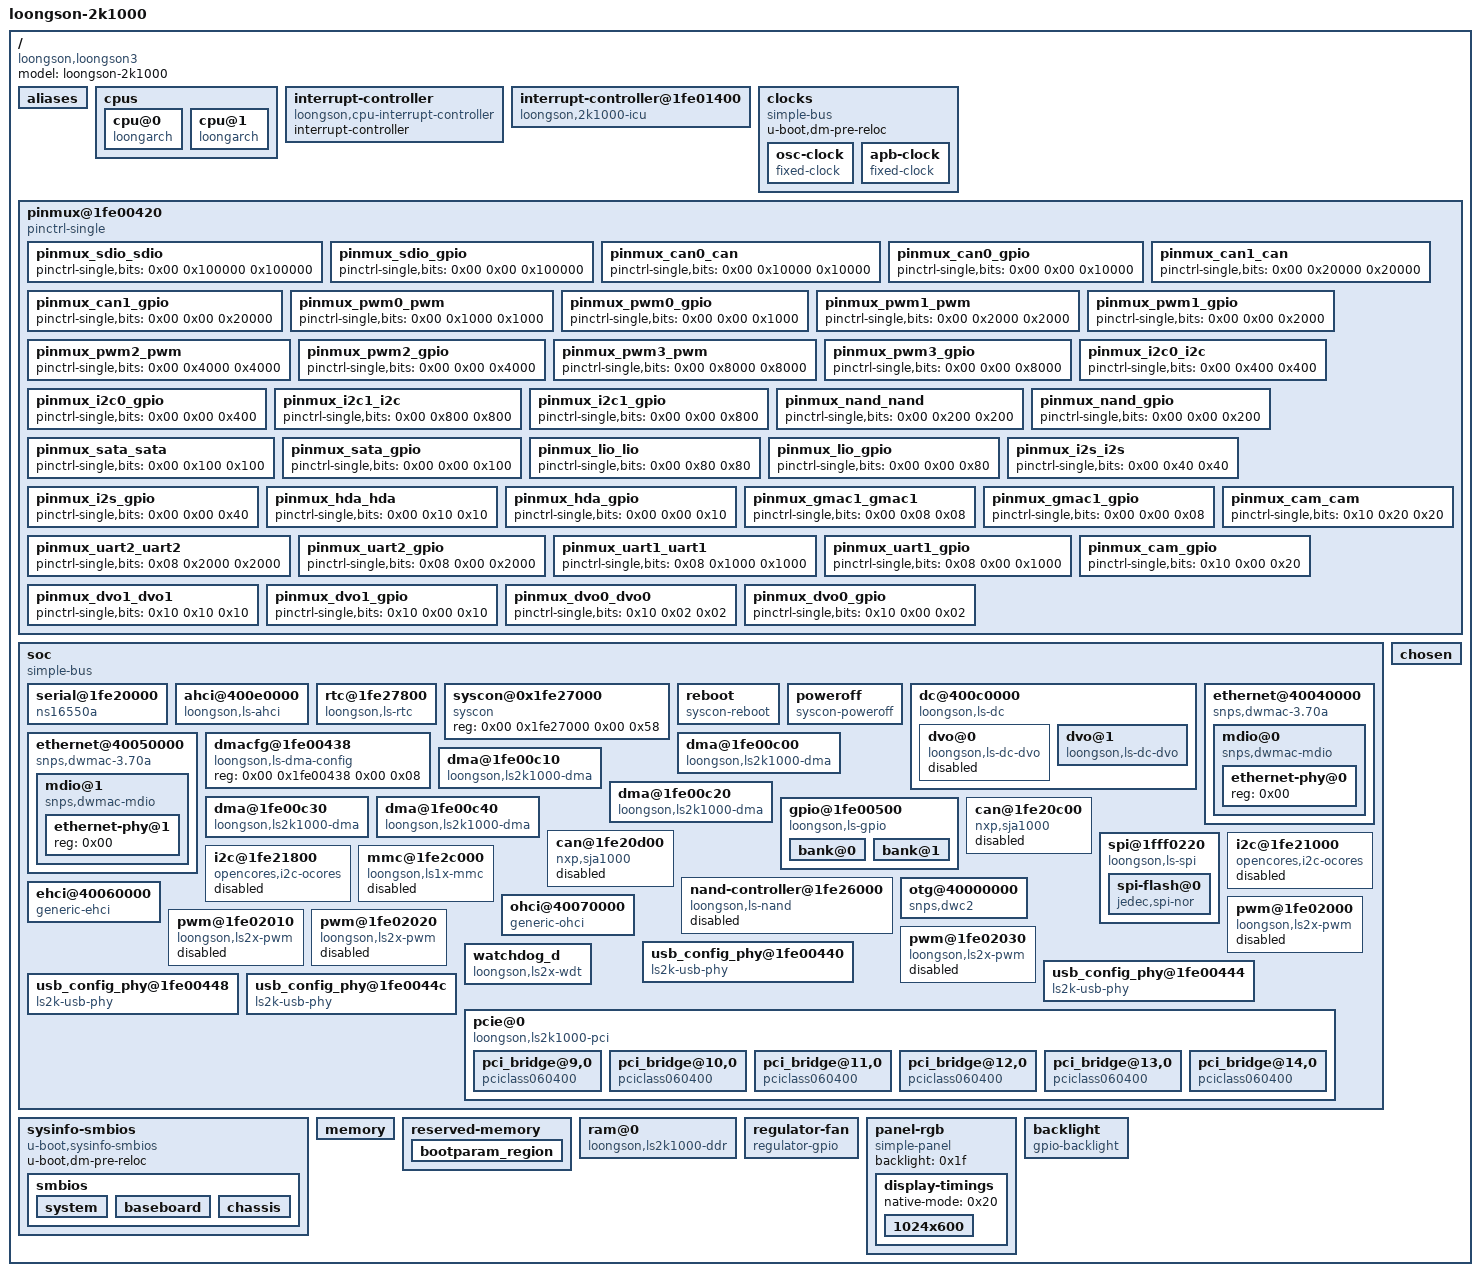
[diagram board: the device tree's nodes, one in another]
/dts-v1/;

/ {
	model = "loongson-2k1000";
	compatible = "loongson,loongson3";
	#address-cells = <0x02>;
	#size-cells = <0x02>;

	aliases {
		ethernet0 = "/soc/ethernet@40040000";
		ethernet1 = "/soc/ethernet@40050000";
		serial0 = "/soc/serial@1fe20000";
		spi0 = "/soc/spi@1fff0220";
	};

	cpus {
		#address-cells = <0x01>;
		#size-cells = <0x00>;

		cpu@0 {
			device_type = "cpu";
			compatible = "loongarch";
			reg = <0x00>;
			numa-node-id = <0x00>;
		};

		cpu@1 {
			device_type = "cpu";
			compatible = "loongarch";
			reg = <0x01>;
			numa-node-id = <0x00>;
		};
	};

	interrupt-controller {
		compatible = "loongson,cpu-interrupt-controller";
		interrupt-controller;
		#interrupt-cells = <0x01>;
		phandle = <0x01>;
	};

	interrupt-controller@1fe01400 {
		compatible = "loongson,2k1000-icu";
		interrupt-controller;
		#interrupt-cells = <0x01>;
		reg = <0x00 0x1fe01400 0x00 0x40 0x00 0x1fe01040 0x00 0x10>;
		interrupt-parent = <0x01>;
		interrupt-names = "cascade";
		interrupts = <0x03>;
		phandle = <0x03>;
	};

	clocks {
		compatible = "simple-bus";
		#address-cells = <0x01>;
		#size-cells = <0x00>;
		u-boot,dm-pre-reloc;

		osc-clock {
			compatible = "fixed-clock";
			#clock-cells = <0x00>;
			clock-frequency = <0x5f5e100>;
			clock-output-names = "osc-clk";
			u-boot,dm-pre-reloc;
			phandle = <0x05>;
		};

		apb-clock {
			compatible = "fixed-clock";
			#clock-cells = <0x00>;
			clock-frequency = <0x7735940>;
			clock-output-names = "apb-clk";
			u-boot,dm-pre-reloc;
			phandle = <0x02>;
		};
	};

	pinmux@1fe00420 {
		compatible = "pinctrl-single";
		reg = <0x80000000 0x1fe00420 0x00 0x18>;
		#address-cells = <0x01>;
		#size-cells = <0x00>;
		#pinctrl-cells = <0x02>;
		pinctrl-single,bit-per-mux;
		pinctrl-single,register-width = <0x20>;
		pinctrl-single,function-mask = <0x01>;

		pinmux_sdio_sdio {
			pinctrl-single,bits = <0x00 0x100000 0x100000>;
			phandle = <0x17>;
		};

		pinmux_sdio_gpio {
			pinctrl-single,bits = <0x00 0x00 0x100000>;
			phandle = <0x12>;
		};

		pinmux_can0_can {
			pinctrl-single,bits = <0x00 0x10000 0x10000>;
		};

		pinmux_can0_gpio {
			pinctrl-single,bits = <0x00 0x00 0x10000>;
		};

		pinmux_can1_can {
			pinctrl-single,bits = <0x00 0x20000 0x20000>;
		};

		pinmux_can1_gpio {
			pinctrl-single,bits = <0x00 0x00 0x20000>;
		};

		pinmux_pwm0_pwm {
			pinctrl-single,bits = <0x00 0x1000 0x1000>;
			phandle = <0x1a>;
		};

		pinmux_pwm0_gpio {
			pinctrl-single,bits = <0x00 0x00 0x1000>;
		};

		pinmux_pwm1_pwm {
			pinctrl-single,bits = <0x00 0x2000 0x2000>;
			phandle = <0x1b>;
		};

		pinmux_pwm1_gpio {
			pinctrl-single,bits = <0x00 0x00 0x2000>;
		};

		pinmux_pwm2_pwm {
			pinctrl-single,bits = <0x00 0x4000 0x4000>;
			phandle = <0x1c>;
		};

		pinmux_pwm2_gpio {
			pinctrl-single,bits = <0x00 0x00 0x4000>;
		};

		pinmux_pwm3_pwm {
			pinctrl-single,bits = <0x00 0x8000 0x8000>;
			phandle = <0x1d>;
		};

		pinmux_pwm3_gpio {
			pinctrl-single,bits = <0x00 0x00 0x8000>;
		};

		pinmux_i2c0_i2c {
			pinctrl-single,bits = <0x00 0x400 0x400>;
			phandle = <0x13>;
		};

		pinmux_i2c0_gpio {
			pinctrl-single,bits = <0x00 0x00 0x400>;
		};

		pinmux_i2c1_i2c {
			pinctrl-single,bits = <0x00 0x800 0x800>;
			phandle = <0x14>;
		};

		pinmux_i2c1_gpio {
			pinctrl-single,bits = <0x00 0x00 0x800>;
		};

		pinmux_nand_nand {
			pinctrl-single,bits = <0x00 0x200 0x200>;
			phandle = <0x15>;
		};

		pinmux_nand_gpio {
			pinctrl-single,bits = <0x00 0x00 0x200>;
			phandle = <0x1e>;
		};

		pinmux_sata_sata {
			pinctrl-single,bits = <0x00 0x100 0x100>;
		};

		pinmux_sata_gpio {
			pinctrl-single,bits = <0x00 0x00 0x100>;
		};

		pinmux_lio_lio {
			pinctrl-single,bits = <0x00 0x80 0x80>;
		};

		pinmux_lio_gpio {
			pinctrl-single,bits = <0x00 0x00 0x80>;
			phandle = <0x06>;
		};

		pinmux_i2s_i2s {
			pinctrl-single,bits = <0x00 0x40 0x40>;
		};

		pinmux_i2s_gpio {
			pinctrl-single,bits = <0x00 0x00 0x40>;
			phandle = <0x22>;
		};

		pinmux_hda_hda {
			pinctrl-single,bits = <0x00 0x10 0x10>;
		};

		pinmux_hda_gpio {
			pinctrl-single,bits = <0x00 0x00 0x10>;
			phandle = <0x21>;
		};

		pinmux_gmac1_gmac1 {
			pinctrl-single,bits = <0x00 0x08 0x08>;
			phandle = <0x0f>;
		};

		pinmux_gmac1_gpio {
			pinctrl-single,bits = <0x00 0x00 0x08>;
		};

		pinmux_uart2_uart2 {
			pinctrl-single,bits = <0x08 0x2000 0x2000>;
		};

		pinmux_uart2_gpio {
			pinctrl-single,bits = <0x08 0x00 0x2000>;
			phandle = <0x08>;
		};

		pinmux_uart1_uart1 {
			pinctrl-single,bits = <0x08 0x1000 0x1000>;
		};

		pinmux_uart1_gpio {
			pinctrl-single,bits = <0x08 0x00 0x1000>;
			phandle = <0x07>;
		};

		pinmux_cam_cam {
			pinctrl-single,bits = <0x10 0x20 0x20>;
		};

		pinmux_cam_gpio {
			pinctrl-single,bits = <0x10 0x00 0x20>;
			phandle = <0x0b>;
		};

		pinmux_dvo1_dvo1 {
			pinctrl-single,bits = <0x10 0x10 0x10>;
			phandle = <0x0c>;
		};

		pinmux_dvo1_gpio {
			pinctrl-single,bits = <0x10 0x00 0x10>;
		};

		pinmux_dvo0_dvo0 {
			pinctrl-single,bits = <0x10 0x02 0x02>;
			phandle = <0x09>;
		};

		pinmux_dvo0_gpio {
			pinctrl-single,bits = <0x10 0x00 0x02>;
		};
	};

	soc {
		compatible = "simple-bus";
		#address-cells = <0x02>;
		#size-cells = <0x02>;
		ranges = <0x00 0x10000000 0x80000000 0x10000000 0x00 0x10000000 0x00 0x2000000 0x80000000 0x2000000 0x00 0x2000000 0x00 0xd000000 0x00 0xd000000 0x00 0x2000000 0x00 0x20000000 0x80000000 0x20000000 0x00 0x10000000 0x00 0x40000000 0x80000000 0x40000000 0x00 0x40000000 0xfe 0x00 0x800000fe 0x00 0x00 0x40000000>;
		dma-coherent;
		u-boot,dm-pre-reloc;
		cam_disable = <0x01>;
		vpu_disable = <0x01>;
		pcie0_enable = <0x00>;
		pcie1_enable = <0x01>;

		serial@1fe20000 {
			compatible = "ns16550a";
			reg = <0x00 0x1fe20000 0x00 0x10>;
			clocks = <0x02>;
			clock-names = "clk";
			interrupt-parent = <0x03>;
			interrupts = <0x00>;
			no-loopback-test;
			u-boot,dm-pre-reloc;
		};

		ahci@400e0000 {
			compatible = "loongson,ls-ahci";
			reg = <0x00 0x400e0000 0x00 0x10000>;
			interrupt-parent = <0x03>;
			interrupts = <0x13>;
			dma-mask = <0x00 0xffffffff>;
		};

		rtc@1fe27800 {
			#address-cells = <0x01>;
			#size-cells = <0x01>;
			compatible = "loongson,ls-rtc";
			reg = <0x00 0x1fe27800 0x00 0x100>;
			interrupt-parent = <0x03>;
			interrupts = <0x34>;
		};

		syscon@0x1fe27000 {
			compatible = "syscon";
			reg = <0x00 0x1fe27000 0x00 0x58>;
			phandle = <0x04>;
		};

		reboot {
			compatible = "syscon-reboot";
			regmap = <0x04>;
			offset = <0x30>;
			mask = <0x01>;
		};

		poweroff {
			compatible = "syscon-poweroff";
			regmap = <0x04>;
			offset = <0x14>;
			mask = <0x3c00>;
			value = <0x3c00>;
		};

		dc@400c0000 {
			compatible = "loongson,ls-dc\0simple-bus";
			reg = <0x00 0x400c0000 0x00 0xffff 0x00 0x1fe004b0 0x00 0x10 0x00 0x1fe004c0 0x00 0x10>;
			#address-cells = <0x01>;
			#size-cells = <0x00>;
			u-boot,dm-pre-reloc;

			dvo@0 {
				compatible = "loongson,ls-dc-dvo";
				reg = <0x00>;
				clocks = <0x05>;
				clock-names = "refclk";
				pix-fmt = "rgb565";
				pinctrl-0 = <0x06 0x07 0x08 0x09>;
				status = "disabled";
			};

			dvo@1 {
				compatible = "loongson,ls-dc-dvo";
				reg = <0x01>;
				clocks = <0x05>;
				clock-names = "refclk";
				pix-fmt = "rgb888";
				ddc-i2c-bus = <0x0a>;
				pinctrl-0 = <0x0b 0x0c>;
				status = "okay";
				connector-type = "panel";
				connector = <0x0d>;
			};
		};

		ethernet@40040000 {
			compatible = "snps,dwmac-3.70a\0snps,arc-dwmac-3.70a";
			reg = <0x00 0x40040000 0x00 0x8000>;
			interrupt-parent = <0x03>;
			interrupts = <0x0c 0x0d>;
			interrupt-names = "macirq\0eth_wake_irq";
			phy-mode = "rgmii";
			bus_id = <0x00>;
			phy_addr = <0xffffffff>;
			phy-handle = <0x0e>;
			dma-mask = <0xffffffff 0xffffffff>;
			status = "okay";

			mdio@0 {
				#address-cells = <0x01>;
				#size-cells = <0x00>;
				compatible = "snps,dwmac-mdio";

				ethernet-phy@0 {
					reg = <0x00>;
					phandle = <0x0e>;
				};
			};
		};

		ethernet@40050000 {
			compatible = "snps,dwmac-3.70a\0snps,arc-dwmac-3.70a";
			reg = <0x00 0x40050000 0x00 0x8000>;
			pinctrl-names = "default";
			pinctrl-0 = <0x0f>;
			interrupt-parent = <0x03>;
			interrupts = <0x0e 0x0f>;
			interrupt-names = "macirq\0eth_wake_irq";
			phy-mode = "rgmii-id";
			bus_id = <0x01>;
			phy_addr = <0xffffffff>;
			phy-handle = <0x10>;
			dma-mask = <0xffffffff 0xffffffff>;
			status = "okay";

			mdio@1 {
				#address-cells = <0x01>;
				#size-cells = <0x00>;
				compatible = "snps,dwmac-mdio";

				ethernet-phy@1 {
					reg = <0x00>;
					phandle = <0x10>;
				};
			};
		};

		dmacfg@1fe00438 {
			compatible = "loongson,ls-dma-config";
			reg = <0x00 0x1fe00438 0x00 0x08>;
			#config-cells = <0x02>;
			phandle = <0x11>;
		};

		dma@1fe00c00 {
			compatible = "loongson,ls2k1000-dma";
			reg = <0x00 0x1fe00c00 0x00 0x08>;
			dma-cfg = <0x11 0x00 0x00>;
			#dma-cells = <0x01>;
			dma-channels = <0x01>;
			dma-requests = <0x01>;
			phandle = <0x16>;
		};

		dma@1fe00c10 {
			compatible = "loongson,ls2k1000-dma";
			reg = <0x00 0x1fe00c10 0x00 0x08>;
			dma-cfg = <0x11 0x01 0x03>;
			#dma-cells = <0x01>;
			dma-channels = <0x01>;
			dma-requests = <0x01>;
		};

		dma@1fe00c20 {
			compatible = "loongson,ls2k1000-dma";
			reg = <0x00 0x1fe00c20 0x00 0x08>;
			dma-cfg = <0x11 0x02 0x04>;
			#dma-cells = <0x01>;
			dma-channels = <0x01>;
			dma-requests = <0x01>;
		};

		dma@1fe00c30 {
			compatible = "loongson,ls2k1000-dma";
			reg = <0x00 0x1fe00c30 0x00 0x08>;
			dma-cfg = <0x11 0x03 0x01>;
			#dma-cells = <0x01>;
			dma-channels = <0x01>;
			dma-requests = <0x01>;
			phandle = <0x18>;
		};

		dma@1fe00c40 {
			compatible = "loongson,ls2k1000-dma";
			reg = <0x00 0x1fe00c40 0x00 0x08>;
			dma-cfg = <0x11 0x03 0x05>;
			#dma-cells = <0x01>;
			dma-channels = <0x01>;
			dma-requests = <0x01>;
		};

		gpio@1fe00500 {
			#address-cells = <0x01>;
			#size-cells = <0x00>;
			compatible = "loongson,ls-gpio";
			reg = <0x00 0x1fe00500 0x00 0x38>;
			pinctrl-0 = <0x12>;
			pinctrl-names = "default";

			bank@0 {
				reg = <0x00>;
				gpio-controller;
				#gpio-cells = <0x02>;
				phandle = <0x23>;
			};

			bank@1 {
				reg = <0x01>;
				gpio-controller;
				#gpio-cells = <0x02>;
				phandle = <0x19>;
			};
		};

		can@1fe20c00 {
			compatible = "nxp,sja1000";
			reg = <0x00 0x1fe20c00 0x00 0x1000>;
			nxp,external-clock-frequency = <0x5f5e100>;
			interrupt-parent = <0x03>;
			interrupts = <0x10>;
			status = "disabled";
		};

		can@1fe20d00 {
			compatible = "nxp,sja1000";
			reg = <0x00 0x1fe20d00 0x00 0x1000>;
			nxp,external-clock-frequency = <0x5f5e100>;
			interrupt-parent = <0x03>;
			interrupts = <0x11>;
			status = "disabled";
		};

		spi@1fff0220 {
			compatible = "loongson,ls-spi";
			reg = <0x00 0x1fff0220 0x00 0x4000>;
			#address-cells = <0x01>;
			#size-cells = <0x00>;
			clocks = <0x05>;
			clock-names = "sclk";
			status = "okay";
			u-boot,dm-pre-reloc;

			spi-flash@0 {
				compatible = "jedec,spi-nor";
				spi-max-frequency = <0x17d7840>;
				reg = <0x00>;
			};
		};

		i2c@1fe21000 {
			compatible = "opencores,i2c-ocores";
			reg = <0x00 0x1fe21000 0x00 0x800>;
			#address-cells = <0x01>;
			#size-cells = <0x00>;
			pinctrl-names = "default";
			pinctrl-0 = <0x13>;
			interrupt-parent = <0x03>;
			interrupts = <0x16>;
			clock-frequency = <0x61a80>;
			reg-shift = <0x00>;
			clocks = <0x02>;
			clock-names = "scl";
			status = "disabled";
		};

		i2c@1fe21800 {
			compatible = "opencores,i2c-ocores";
			reg = <0x00 0x1fe21800 0x00 0x800>;
			#address-cells = <0x01>;
			#size-cells = <0x00>;
			pinctrl-names = "default";
			pinctrl-0 = <0x14>;
			interrupt-parent = <0x03>;
			interrupts = <0x17>;
			clock-frequency = <0x61a80>;
			reg-shift = <0x00>;
			clocks = <0x02>;
			clock-names = "scl";
			status = "disabled";
			phandle = <0x0a>;
		};

		nand-controller@1fe26000 {
			compatible = "loongson,ls-nand";
			reg = <0x00 0x1fe26000 0x00 0x44>;
			pinctrl-names = "default";
			pinctrl-0 = <0x15>;
			dmas = <0x16 0x00>;
			dma-names = "nand-rw";
			nand-cs-origin = <0x02>;
			nand-ecc-algo = "bch";
			nand-ecc-strength = <0x04>;
			status = "disabled";
		};

		mmc@1fe2c000 {
			compatible = "loongson,ls1x-mmc";
			reg = <0x00 0x1fe2c000 0x00 0x1000>;
			pinctrl-names = "default";
			pinctrl-0 = <0x17>;
			dmas = <0x18 0x00>;
			dma-names = "sdio0";
			cap-sd-highspeed;
			cap-mmc-highspeed;
			status = "disabled";
		};

		otg@40000000 {
			compatible = "snps,dwc2";
			reg = <0x00 0x40000000 0x00 0x40000>;
			interrupt-parent = <0x03>;
			interrupts = <0x31>;
			dma-mask = <0x00 0xffffffff>;
			status = "okay";
		};

		ehci@40060000 {
			compatible = "generic-ehci";
			reg = <0x00 0x40060000 0x00 0x8000>;
			dma-mask = <0x00 0xffffffff>;
			pinctrl-names = "default";
			gpios = <0x19 0x18 0x00>;
		};

		ohci@40070000 {
			compatible = "generic-ohci";
			reg = <0x00 0x40070000 0x00 0x8000>;
			dma-mask = <0x00 0xffffffff>;
		};

		pwm@1fe02000 {
			compatible = "loongson,ls2x-pwm";
			#pwm-cells = <0x03>;
			reg = <0x00 0x1fe02000 0x00 0x0f>;
			interrupt-parent = <0x03>;
			interrupts = <0x18>;
			pinctrl-names = "default";
			pinctrl-0 = <0x1a>;
			status = "disabled";
		};

		pwm@1fe02010 {
			compatible = "loongson,ls2x-pwm";
			#pwm-cells = <0x03>;
			reg = <0x00 0x1fe02010 0x00 0x0f>;
			interrupt-parent = <0x03>;
			interrupts = <0x19>;
			pinctrl-names = "default";
			pinctrl-0 = <0x1b>;
			status = "disabled";
		};

		pwm@1fe02020 {
			compatible = "loongson,ls2x-pwm";
			#pwm-cells = <0x03>;
			reg = <0x00 0x1fe02020 0x00 0x0f>;
			interrupt-parent = <0x03>;
			interrupts = <0x1a>;
			pinctrl-names = "default";
			pinctrl-0 = <0x1c>;
			status = "disabled";
		};

		pwm@1fe02030 {
			compatible = "loongson,ls2x-pwm";
			#pwm-cells = <0x03>;
			reg = <0x00 0x1fe02030 0x00 0x0f>;
			interrupt-parent = <0x03>;
			interrupts = <0x1b>;
			pinctrl-names = "default";
			pinctrl-0 = <0x1d>;
			status = "disabled";
		};

		usb_config_phy@1fe00440 {
			compatible = "ls2k-usb-phy";
			reg = <0x00 0x1fe00440 0x00 0x04>;
			status = "okay";
			tx_res_tune = <0x03>;
			tx_hsxv_tune = <0x02>;
			tx_fsls_tune = <0x03>;
			compdis_tune = <0x04>;
		};

		usb_config_phy@1fe00444 {
			compatible = "ls2k-usb-phy";
			reg = <0x00 0x1fe00444 0x00 0x04>;
			status = "okay";
			tx_res_tune = <0x03>;
			tx_hsxv_tune = <0x02>;
			tx_fsls_tune = <0x03>;
			compdis_tune = <0x04>;
		};

		usb_config_phy@1fe00448 {
			compatible = "ls2k-usb-phy";
			reg = <0x00 0x1fe00448 0x00 0x04>;
			status = "okay";
			tx_res_tune = <0x03>;
			tx_hsxv_tune = <0x02>;
			tx_fsls_tune = <0x03>;
			compdis_tune = <0x04>;
		};

		usb_config_phy@1fe0044c {
			compatible = "ls2k-usb-phy";
			reg = <0x00 0x1fe0044c 0x00 0x04>;
			status = "okay";
			tx_res_tune = <0x03>;
			tx_hsxv_tune = <0x02>;
			tx_fsls_tune = <0x03>;
			compdis_tune = <0x04>;
		};

		watchdog_d {
			compatible = "loongson,ls2x-wdt";
			reg = <0x00 0x1fe27030 0x00 0x0c>;
			clocks = <0x02>;
			clock-names = "clk";
			status = "okay";
		};

		pcie@0 {
			compatible = "loongson,ls2k1000-pci";
			#interrupt-cells = <0x01>;
			bus-range = <0x01 0x16>;
			#size-cells = <0x02>;
			#address-cells = <0x03>;
			reg = <0xfe 0x00 0x00 0x20000000>;
			ranges = <0x2000000 0x00 0x60000000 0x00 0x60000000 0x00 0x20000000 0x1000000 0x00 0x8000 0x00 0x18008000 0x00 0x8000>;

			pci_bridge@9,0 {
				compatible = "pciclass060400\0pciclass0604";
				reg = <0x4800 0x00 0x00 0x00 0x00>;
				interrupts = <0x20>;
				interrupt-parent = <0x03>;
				#interrupt-cells = <0x01>;
				interrupt-map-mask = <0x00 0x00 0x00 0x00>;
				interrupt-map = <0x00 0x00 0x00 0x00 0x03 0x20>;
			};

			pci_bridge@10,0 {
				compatible = "pciclass060400\0pciclass0604";
				reg = <0x5000 0x00 0x00 0x00 0x00>;
				interrupts = <0x21>;
				interrupt-parent = <0x03>;
				#interrupt-cells = <0x01>;
				interrupt-map-mask = <0x00 0x00 0x00 0x00>;
				interrupt-map = <0x00 0x00 0x00 0x00 0x03 0x21>;
			};

			pci_bridge@11,0 {
				compatible = "pciclass060400\0pciclass0604";
				reg = <0x5800 0x00 0x00 0x00 0x00>;
				interrupts = <0x22>;
				interrupt-parent = <0x03>;
				#interrupt-cells = <0x01>;
				interrupt-map-mask = <0x00 0x00 0x00 0x00>;
				interrupt-map = <0x00 0x00 0x00 0x00 0x03 0x22>;
			};

			pci_bridge@12,0 {
				compatible = "pciclass060400\0pciclass0604";
				reg = <0x6000 0x00 0x00 0x00 0x00>;
				interrupts = <0x23>;
				interrupt-parent = <0x03>;
				#interrupt-cells = <0x01>;
				interrupt-map-mask = <0x00 0x00 0x00 0x00>;
				interrupt-map = <0x00 0x00 0x00 0x00 0x03 0x23>;
			};

			pci_bridge@13,0 {
				compatible = "pciclass060400\0pciclass0604";
				reg = <0x6800 0x00 0x00 0x00 0x00>;
				interrupts = <0x24>;
				interrupt-parent = <0x03>;
				#interrupt-cells = <0x01>;
				interrupt-map-mask = <0x00 0x00 0x00 0x00>;
				interrupt-map = <0x00 0x00 0x00 0x00 0x03 0x24>;
			};

			pci_bridge@14,0 {
				compatible = "pciclass060400\0pciclass0604";
				reg = <0x7000 0x00 0x00 0x00 0x00>;
				interrupts = <0x25>;
				interrupt-parent = <0x03>;
				#interrupt-cells = <0x01>;
				interrupt-map-mask = <0x00 0x00 0x00 0x00>;
				interrupt-map = <0x00 0x00 0x00 0x00 0x03 0x25>;
			};
		};
	};

	chosen {
		stdout-path = "serial0:115200n8";
		bootargs = "earlycon";
	};

	sysinfo-smbios {
		compatible = "u-boot,sysinfo-smbios";
		u-boot,dm-pre-reloc;

		smbios {

			system {
				manufacturer = "Loongson";
				product = "LS2K1000";
			};

			baseboard {
				manufacturer = "Loongson";
				product = "LS2K1000-DP";
			};

			chassis {
				manufacturer = "Loongson";
				product = "LS2K1000-DP";
			};
		};
	};

	memory {
		device_type = "memory";
		reg = <0x90000000 0x00 0x00 0x10000000 0x90000000 0x90000000 0x00 0x30000000>;
		u-boot,dm-pre-reloc;
	};

	reserved-memory {
		#address-cells = <0x02>;
		#size-cells = <0x02>;
		ranges;

		bootparam_region {
			reg = <0x90000000 0xf000000 0x00 0x1000000>;
			no-map;
		};
	};

	ram@0 {
		compatible = "loongson,ls2k1000-ddr";
		u-boot,dm-pre-reloc;
		soc-config-reg = <0x1fe00424>;
		mc-disable-offs = <0x08>;
		mc-default-offs = <0x09>;
		sdram-type = "ddr3";
		dimm-type = "udimm";
		cs-map = <0x01>;
		data-width = <0x20>;
		sdram-width = <0x10>;
		sdram-banks = <0x08>;
		sdram-rows = <0x0f>;
		sdram-cols = <0x0a>;
		clk-latency = <0x30>;
		rd-latency = <0x09>;
		wr-latency = <0x04>;
		cmd-timing-mode = <0x01>;
		reset-revert;
	};

	regulator-fan {
		compatible = "regulator-gpio";
		pinctrl-0 = <0x1e>;
		pinctrl-names = "default";
		regulator-name = "vdd-fan";
		regulator-min-microvolt = <0x00>;
		regulator-max-microvolt = <0xb71b00>;
		regulator-init-microvolt = <0xb71b00>;
		regulator-type = "voltage";
		regulator-boot-on;
		regulator-always-on;
		enable-active-high;
		states = <0x00 0x00 0xb71b00 0x01>;
		gpios = <0x19 0x19 0x00>;
	};

	panel-rgb {
		compatible = "simple-panel";
		backlight = <0x1f>;
		phandle = <0x0d>;

		display-timings {
			native-mode = <0x20>;

			1024x600 {
				clock-frequency = <0x30d4000>;
				hactive = <0x400>;
				vactive = <0x258>;
				hsync-len = <0x14>;
				hfront-porch = <0xa0>;
				hback-porch = <0x8c>;
				vfront-porch = <0x0c>;
				vback-porch = <0x14>;
				vsync-len = <0x03>;
				de-active = <0x01>;
				hsync-active = <0x00>;
				vsync-active = <0x00>;
				pixelclk-active = <0x00>;
				phandle = <0x20>;
			};
		};
	};

	backlight {
		compatible = "gpio-backlight";
		pinctrl-0 = <0x21 0x22>;
		pinctrl-names = "default";
		gpios = <0x23 0x18 0x00>;
		phandle = <0x1f>;
	};
};
